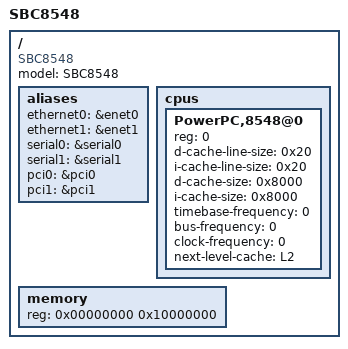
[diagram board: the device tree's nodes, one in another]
// SPDX-License-Identifier: GPL-2.0-or-later
/*
 * SBC8548 Device Tree Source
 *
 * Copyright 2007 Wind River Systems Inc.
 *
 * Paul Gortmaker (see MAINTAINERS for contact information)
 */

/{
	model = "SBC8548";
	compatible = "SBC8548";
	#address-cells = <1>;
	#size-cells = <1>;

	aliases {
		ethernet0 = &enet0;
		ethernet1 = &enet1;
		serial0 = &serial0;
		serial1 = &serial1;
		pci0 = &pci0;
		pci1 = &pci1;
	};

	cpus {
		#address-cells = <1>;
		#size-cells = <0>;

		PowerPC,8548@0 {
			device_type = "cpu";
			reg = <0>;
			d-cache-line-size = <0x20>;	// 32 bytes
			i-cache-line-size = <0x20>;	// 32 bytes
			d-cache-size = <0x8000>;	// L1, 32K
			i-cache-size = <0x8000>;	// L1, 32K
			timebase-frequency = <0>;	// From uboot
			bus-frequency = <0>;
			clock-frequency = <0>;
			next-level-cache = <&L2>;
		};
	};

	memory {
		device_type = "memory";
		reg = <0x00000000 0x10000000>;
	};

};
